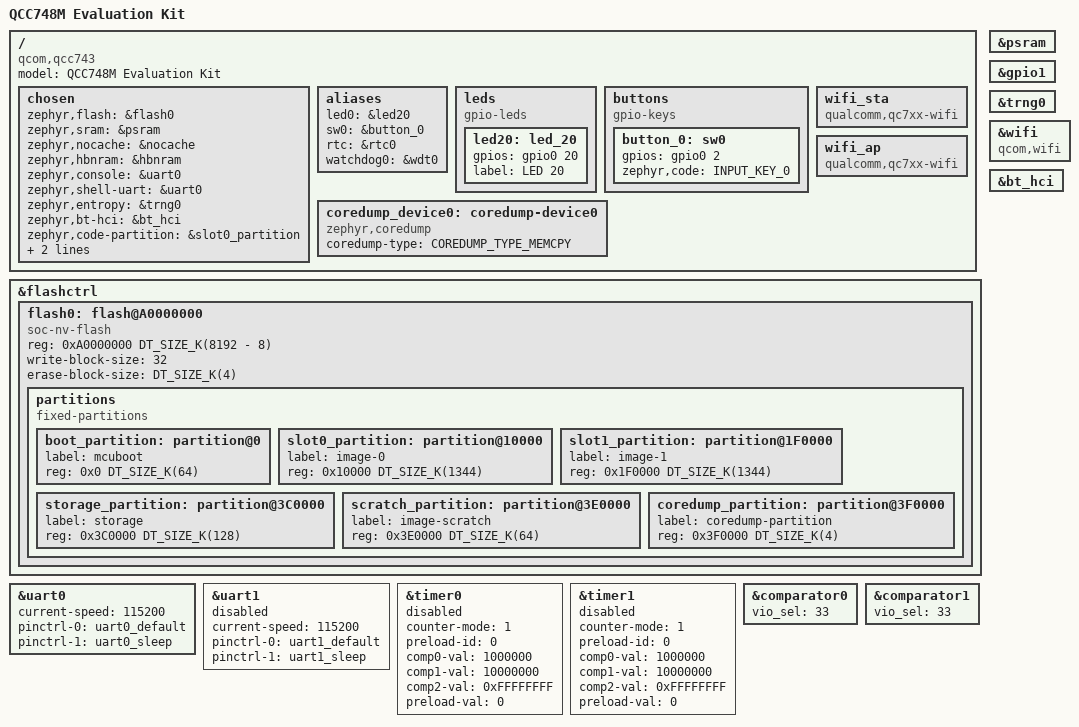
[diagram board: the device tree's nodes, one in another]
/*
 * Copyright (c) 2026 Qualcomm Technologies, Inc. and/or its subsidiaries
 *
 * SPDX-License-Identifier: Apache-2.0
 */

/dts-v1/;

#include <qcom/qcc74x/qcc748.dtsi>
#include <zephyr/dt-bindings/input/input-event-codes.h>
#include "qcc748m_evk-pinctrl.dtsi"

/ {
	model = "QCC748M Evaluation Kit";
	compatible = "qcom,qcc743";

	chosen {
		zephyr,flash = &flash0;
		zephyr,sram = &psram;
		zephyr,nocache = &nocache;
		zephyr,hbnram = &hbnram;
		zephyr,console = &uart0;
		zephyr,shell-uart = &uart0;
		zephyr,entropy = &trng0;
		zephyr,bt-hci = &bt_hci;
		zephyr,code-partition = &slot0_partition;
		zephyr,clock-controller = &clock0;
		zephyr,flash-controller = &flashctrl;
	};

	aliases {
		led0 = &led20;
		sw0 = &button_0;
		rtc = &rtc0;
		watchdog0 = &wdt0;
	};

	leds {
		compatible = "gpio-leds";
		led20: led_20 {
			gpios =  <&gpio0 20 GPIO_ACTIVE_HIGH>;
			label = "LED 20";
		};
	};

	buttons {
		compatible = "gpio-keys";
		button_0: sw0 {
			gpios = <&gpio0 2 (GPIO_PULL_DOWN | GPIO_ACTIVE_HIGH)>;
			zephyr,code = <INPUT_KEY_0>;
		};
	};
};

/ {
	coredump_device0: coredump-device0 {
		compatible = "zephyr,coredump";
		coredump-type = "COREDUMP_TYPE_MEMCPY";
		status = "okay";
	};
};

&flashctrl {
	flash0: flash@A0000000 {
		compatible = "soc-nv-flash";
		reg = <0xA0000000 DT_SIZE_K(8192 - 8)>;
		write-block-size = <32>;
		erase-block-size = <DT_SIZE_K(4)>;
		status = "okay";

		partitions {
			compatible = "fixed-partitions";
			#address-cells = <1>;
			#size-cells = <1>;

			boot_partition: partition@0 {
				label = "mcuboot";
				reg = <0x0 DT_SIZE_K(64)>;
			};

			slot0_partition: partition@10000 {
				label = "image-0";
				reg = <0x10000 DT_SIZE_K(1344)>;
			};

			slot1_partition: partition@1F0000 {
				label = "image-1";
				reg = <0x1F0000 DT_SIZE_K(1344)>;
			};

			storage_partition: partition@3C0000 {
				label = "storage";
				reg = <0x3C0000 DT_SIZE_K(128)>;
			};

			scratch_partition: partition@3E0000 {
				label = "image-scratch";
				reg = <0x3E0000 DT_SIZE_K(64)>;
			};

			coredump_partition: partition@3F0000 {
				label = "coredump-partition";
				reg = <0x3F0000 DT_SIZE_K(4)>;
			};
		};
	};
};

&psram {
	status = "okay";
};

&uart0 {
	status = "okay";
	current-speed = <115200>;
	pinctrl-0 = <&uart0_default>;
	pinctrl-1 = <&uart0_sleep>;
	pinctrl-names = "default", "sleep";
};

&uart1 {
	status = "disabled";
	current-speed = <115200>;
	pinctrl-0 = <&uart1_default>;
	pinctrl-1 = <&uart1_sleep>;
	pinctrl-names = "default", "sleep";
};

&gpio1 {
	status = "okay";
};

&trng0 {
	status = "okay";
};

&timer0 {
	status = "disabled";
	counter-mode = <1>;
	preload-id = <0>;
	comp0-val = <1000000>;
	comp1-val = <10000000>;
	comp2-val = <0xFFFFFFFF>;
	preload-val = <0>;
};

&timer1 {
	status = "disabled";
	counter-mode = <1>;
	preload-id = <0>;
	comp0-val = <1000000>;
	comp1-val = <10000000>;
	comp2-val = <0xFFFFFFFF>;
	preload-val = <0>;
};

&comparator0 {
	vio_sel = <33>;
};

&comparator1 {
	vio_sel = <33>;
};

&wifi {
	compatible = "qcom,wifi";
	status = "okay";
};

/ {
	wifi_sta: wifi_sta {
		compatible = "qualcomm,qc7xx-wifi";
		status = "okay";
	};
	wifi_ap: wifi_ap {
		compatible = "qualcomm,qc7xx-wifi";
		status = "okay";
	};
};

&bt_hci {
	status = "okay";
};
